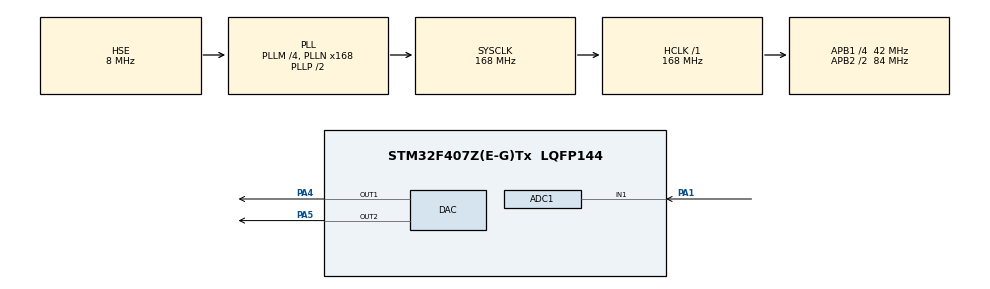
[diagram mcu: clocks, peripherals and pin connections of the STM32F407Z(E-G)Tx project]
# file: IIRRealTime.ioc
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ADC1.Channel-0\#ChannelRegularConversion=ADC_CHANNEL_1
ADC1.DMAContinuousRequests=ENABLE
ADC1.ExternalTrigConv=ADC_EXTERNALTRIGCONV_T8_TRGO
ADC1.NbrOfConversionFlag=1
ADC1.Rank-0\#ChannelRegularConversion=1
ADC1.SamplingTime-0\#ChannelRegularConversion=ADC_SAMPLETIME_3CYCLES
ADC1.master=1
DAC.DAC_Trigger=DAC_TRIGGER_T8_TRGO
DAC.DAC_Trigger2=DAC_TRIGGER_T8_TRGO
Dma.ADC1.0.Direction=DMA_PERIPH_TO_MEMORY
Dma.ADC1.0.FIFOMode=DMA_FIFOMODE_DISABLE
Dma.ADC1.0.Instance=DMA2_Stream0
Dma.ADC1.0.MemDataAlignment=DMA_MDATAALIGN_WORD
Dma.ADC1.0.MemInc=DMA_MINC_ENABLE
Dma.ADC1.0.Mode=DMA_CIRCULAR
Dma.ADC1.0.PeriphDataAlignment=DMA_PDATAALIGN_WORD
Dma.ADC1.0.PeriphInc=DMA_PINC_DISABLE
Dma.ADC1.0.Priority=DMA_PRIORITY_HIGH
Dma.DAC1.1.Direction=DMA_MEMORY_TO_PERIPH
Dma.DAC1.1.FIFOMode=DMA_FIFOMODE_DISABLE
Dma.DAC1.1.Instance=DMA1_Stream5
Dma.DAC1.1.MemDataAlignment=DMA_MDATAALIGN_WORD
Dma.DAC1.1.MemInc=DMA_MINC_ENABLE
Dma.DAC1.1.Mode=DMA_CIRCULAR
Dma.DAC1.1.PeriphDataAlignment=DMA_PDATAALIGN_WORD
Dma.DAC1.1.PeriphInc=DMA_PINC_DISABLE
Dma.DAC1.1.Priority=DMA_PRIORITY_HIGH
Dma.DAC2.2.Direction=DMA_MEMORY_TO_PERIPH
Dma.DAC2.2.FIFOMode=DMA_FIFOMODE_DISABLE
Dma.DAC2.2.Instance=DMA1_Stream6
Dma.DAC2.2.MemDataAlignment=DMA_MDATAALIGN_WORD
Dma.DAC2.2.MemInc=DMA_MINC_ENABLE
Dma.DAC2.2.Mode=DMA_CIRCULAR
Dma.DAC2.2.PeriphDataAlignment=DMA_PDATAALIGN_WORD
Dma.DAC2.2.PeriphInc=DMA_PINC_DISABLE
Dma.DAC2.2.Priority=DMA_PRIORITY_HIGH
Dma.Request0=ADC1
Dma.Request1=DAC1
Dma.Request2=DAC2
Mcu.Family=STM32F4
Mcu.Name=STM32F407Z(E-G)Tx
Mcu.Package=LQFP144
NVIC.DMA1_Stream5_IRQn=true\:0\:0\:false\:false\:true\:false\:true\:true
NVIC.DMA1_Stream6_IRQn=true\:0\:0\:false\:false\:true\:false\:true\:true
NVIC.DMA2_Stream0_IRQn=true\:0\:0\:false\:false\:true\:false\:true\:true
NVIC.PriorityGroup=NVIC_PRIORITYGROUP_4
PA1.Signal=ADCx_IN1
PA13.Mode=Serial_Wire
PA13.Signal=SYS_JTMS-SWDIO
PA14.Mode=Serial_Wire
PA14.Signal=SYS_JTCK-SWCLK
PA4.Signal=COMP_DAC1_group
PA5.Signal=COMP_DAC2_group
PH0-OSC_IN.Mode=HSE-External-Oscillator
PH0-OSC_IN.Signal=RCC_OSC_IN
PH1-OSC_OUT.Mode=HSE-External-Oscillator
PH1-OSC_OUT.Signal=RCC_OSC_OUT
ProjectManager.HeapSize=0x200
ProjectManager.StackSize=0x400
ProjectManager.TargetToolchain=STM32CubeIDE
RCC.48MHZClocksFreq_Value=84000000
RCC.AHBFreq_Value=168000000
RCC.APB1CLKDivider=RCC_HCLK_DIV4
RCC.APB1Freq_Value=42000000
RCC.APB1TimFreq_Value=84000000
RCC.APB2CLKDivider=RCC_HCLK_DIV2
RCC.APB2Freq_Value=84000000
RCC.APB2TimFreq_Value=168000000
RCC.CortexFreq_Value=168000000
RCC.HCLKFreq_Value=168000000
RCC.HSE_VALUE=8000000
RCC.HSI_VALUE=16000000
RCC.LSE_VALUE=32768
RCC.PLLM=4
RCC.PLLN=168
RCC.PLLSourceVirtual=RCC_PLLSOURCE_HSE
RCC.SYSCLKFreq_VALUE=168000000
RCC.SYSCLKSource=RCC_SYSCLKSOURCE_PLLCLK
RCC.VCOOutputFreq_Value=336000000
SH.ADCx_IN1.0=ADC1_IN1,IN1
SH.COMP_DAC1_group.0=DAC_OUT1,DAC_OUT1
SH.COMP_DAC2_group.0=DAC_OUT2,DAC_OUT2
TIM5.AutoReloadPreload=TIM_AUTORELOAD_PRELOAD_ENABLE
TIM5.Prescaler=83
TIM8.Period=3499
TIM8.TIM_MasterOutputTrigger=TIM_TRGO_UPDATE
VP_TIM5_VS_ClockSourceINT.Mode=Internal
VP_TIM8_VS_ClockSourceINT.Mode=Internal
board=custom

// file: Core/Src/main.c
/* USER CODE BEGIN Header */
/**
  ******************************************************************************
  * @file           : main.c
  * @brief          : Main program body
  ******************************************************************************
  * @attention
  *
  * Copyright (c) 2024 STMicroelectronics.
  * All rights reserved.
  *
  * This software is licensed under terms that can be found in the LICENSE file
  * in the root directory of this software component.
  * If no LICENSE file comes with this software, it is provided AS-IS.
  *
  ******************************************************************************
  */
/* USER CODE END Header */
#include "main.h"

/* USER CODE BEGIN Includes */
#include <string.h>

#define ARM_MATH_CM4

#include "arm_math.h"
/* USER CODE END Includes */

ADC_HandleTypeDef hadc1;
DMA_HandleTypeDef hdma_adc1;

DAC_HandleTypeDef hdac;
DMA_HandleTypeDef hdma_dac1;
DMA_HandleTypeDef hdma_dac2;

TIM_HandleTypeDef htim5;
TIM_HandleTypeDef htim8;

/* USER CODE BEGIN PV */

float32_t aIIR_F32_Coeffs[20] = {
	1,2.03045971006842,1.030928964547704,0.8350734723870988,-0.1809722302276889,
	1,1.99965252497197,1.000116453042647,0.8905975796378678,-0.2594951757406769,
	1,1.969540231281527,0.9699989009856418,1.015339858454558,-0.4359073982444064,
	1,2.000347533678088,0.9998835979072017,1.242773362694666,-0.7575469444788124
};

float32_t iirStateF32[16];

arm_biquad_casd_df1_inst_f32 IIR_F32_Struct;

//ADC DAC buffer
uint32_t adc_data[256];
uint32_t dac_data[256];
uint32_t sin_data[256];

float inBuffer[128];
float outBuffer[128];

uint32_t outDacFilter;
uint32_t outDacSignalGen;

uint8_t freq = 1;

/* USER CODE END PV */

void SystemClock_Config(void);
static void MX_GPIO_Init(void);
static void MX_DMA_Init(void);
static void MX_TIM5_Init(void);
static void MX_ADC1_Init(void);
static void MX_TIM8_Init(void);
static void MX_DAC_Init(void);
/* USER CODE BEGIN PFP */
void II_RProcess(void);
/* USER CODE END PFP */

int main(void)
{

  /* MCU Configuration--------------------------------------------------------*/

  /* Reset of all peripherals, Initializes the Flash interface and the Systick. */
  HAL_Init();

  /* Configure the system clock */
  SystemClock_Config();

  /* Initialize all configured peripherals */
  MX_GPIO_Init();
  MX_DMA_Init();
  MX_TIM5_Init();
  MX_ADC1_Init();
  MX_TIM8_Init();
  MX_DAC_Init();
  /* USER CODE BEGIN 2 */

  //generate output sin wave form
  for (int i = 0; i < 255; i++) {
	  sin_data[i] = (uint32_t)(1000*(sin(freq*2*3.1416*(((float)i)/256))+1));
  }

  arm_biquad_cascade_df1_init_f32(&IIR_F32_Struct, 4, aIIR_F32_Coeffs, iirStateF32);
  HAL_TIM_Base_Start(&htim8);
  HAL_ADC_Start_DMA(&hadc1, (uint32_t *) adc_data, 256);
  HAL_DAC_Start_DMA(&hdac, DAC_CHANNEL_1, (uint32_t *) dac_data, 256, DAC_ALIGN_12B_R);
  HAL_DAC_Start_DMA(&hdac, DAC_CHANNEL_2, (uint32_t *) sin_data, 256, DAC_ALIGN_12B_R);
  /* USER CODE END 2 */

  /* Infinite loop */
  while (1)
  {

  }
}

void SystemClock_Config(void)
{
  RCC_OscInitTypeDef RCC_OscInitStruct = {0};
  RCC_ClkInitTypeDef RCC_ClkInitStruct = {0};

  /** Configure the main internal regulator output voltage
  */
  __HAL_RCC_PWR_CLK_ENABLE();
  __HAL_PWR_VOLTAGESCALING_CONFIG(PWR_REGULATOR_VOLTAGE_SCALE1);

  /** Initializes the RCC Oscillators according to the specified parameters
  * in the RCC_OscInitTypeDef structure.
  */
  RCC_OscInitStruct.OscillatorType = RCC_OSCILLATORTYPE_HSE;
  RCC_OscInitStruct.HSEState = RCC_HSE_ON;
  RCC_OscInitStruct.PLL.PLLState = RCC_PLL_ON;
  RCC_OscInitStruct.PLL.PLLSource = RCC_PLLSOURCE_HSE;
  RCC_OscInitStruct.PLL.PLLM = 4;
  RCC_OscInitStruct.PLL.PLLN = 168;
  RCC_OscInitStruct.PLL.PLLP = RCC_PLLP_DIV2;
  RCC_OscInitStruct.PLL.PLLQ = 4;
  if (HAL_RCC_OscConfig(&RCC_OscInitStruct) != HAL_OK)
  {
    Error_Handler();
  }

  /** Initializes the CPU, AHB and APB buses clocks
  */
  RCC_ClkInitStruct.ClockType = RCC_CLOCKTYPE_HCLK|RCC_CLOCKTYPE_SYSCLK
                              |RCC_CLOCKTYPE_PCLK1|RCC_CLOCKTYPE_PCLK2;
  RCC_ClkInitStruct.SYSCLKSource = RCC_SYSCLKSOURCE_PLLCLK;
  RCC_ClkInitStruct.AHBCLKDivider = RCC_SYSCLK_DIV1;
  RCC_ClkInitStruct.APB1CLKDivider = RCC_HCLK_DIV4;
  RCC_ClkInitStruct.APB2CLKDivider = RCC_HCLK_DIV2;

  if (HAL_RCC_ClockConfig(&RCC_ClkInitStruct, FLASH_LATENCY_5) != HAL_OK)
  {
    Error_Handler();
  }
}

static void MX_ADC1_Init(void)
{

  ADC_ChannelConfTypeDef sConfig = {0};

  /** Configure the global features of the ADC (Clock, Resolution, Data Alignment and number of conversion)
  */
  hadc1.Instance = ADC1;
  hadc1.Init.ClockPrescaler = ADC_CLOCK_SYNC_PCLK_DIV4;
  hadc1.Init.Resolution = ADC_RESOLUTION_12B;
  hadc1.Init.ScanConvMode = DISABLE;
  hadc1.Init.ContinuousConvMode = DISABLE;
  hadc1.Init.DiscontinuousConvMode = DISABLE;
  hadc1.Init.ExternalTrigConvEdge = ADC_EXTERNALTRIGCONVEDGE_RISING;
  hadc1.Init.ExternalTrigConv = ADC_EXTERNALTRIGCONV_T8_TRGO;
  hadc1.Init.DataAlign = ADC_DATAALIGN_RIGHT;
  hadc1.Init.NbrOfConversion = 1;
  hadc1.Init.DMAContinuousRequests = ENABLE;
  hadc1.Init.EOCSelection = ADC_EOC_SINGLE_CONV;
  if (HAL_ADC_Init(&hadc1) != HAL_OK)
  {
    Error_Handler();
  }

  /** Configure for the selected ADC regular channel its corresponding rank in the sequencer and its sample time.
  */
  sConfig.Channel = ADC_CHANNEL_1;
  sConfig.Rank = 1;
  sConfig.SamplingTime = ADC_SAMPLETIME_3CYCLES;
  if (HAL_ADC_ConfigChannel(&hadc1, &sConfig) != HAL_OK)
  {
    Error_Handler();
  }

}

static void MX_DAC_Init(void)
{

  DAC_ChannelConfTypeDef sConfig = {0};

  /** DAC Initialization
  */
  hdac.Instance = DAC;
  if (HAL_DAC_Init(&hdac) != HAL_OK)
  {
    Error_Handler();
  }

  /** DAC channel OUT1 config
  */
  sConfig.DAC_Trigger = DAC_TRIGGER_T8_TRGO;
  sConfig.DAC_OutputBuffer = DAC_OUTPUTBUFFER_ENABLE;
  if (HAL_DAC_ConfigChannel(&hdac, &sConfig, DAC_CHANNEL_1) != HAL_OK)
  {
    Error_Handler();
  }

  /** DAC channel OUT2 config
  */
  if (HAL_DAC_ConfigChannel(&hdac, &sConfig, DAC_CHANNEL_2) != HAL_OK)
  {
    Error_Handler();
  }

}

static void MX_TIM5_Init(void)
{

  TIM_ClockConfigTypeDef sClockSourceConfig = {0};
  TIM_MasterConfigTypeDef sMasterConfig = {0};

  htim5.Instance = TIM5;
  htim5.Init.Prescaler = 83;
  htim5.Init.CounterMode = TIM_COUNTERMODE_UP;
  htim5.Init.Period = 4294967295;
  htim5.Init.ClockDivision = TIM_CLOCKDIVISION_DIV1;
  htim5.Init.AutoReloadPreload = TIM_AUTORELOAD_PRELOAD_ENABLE;
  if (HAL_TIM_Base_Init(&htim5) != HAL_OK)
  {
    Error_Handler();
  }
  sClockSourceConfig.ClockSource = TIM_CLOCKSOURCE_INTERNAL;
  if (HAL_TIM_ConfigClockSource(&htim5, &sClockSourceConfig) != HAL_OK)
  {
    Error_Handler();
  }
  sMasterConfig.MasterOutputTrigger = TIM_TRGO_RESET;
  sMasterConfig.MasterSlaveMode = TIM_MASTERSLAVEMODE_DISABLE;
  if (HAL_TIMEx_MasterConfigSynchronization(&htim5, &sMasterConfig) != HAL_OK)
  {
    Error_Handler();
  }
  /* USER CODE BEGIN TIM5_Init 2 */
  HAL_TIM_Base_Start(&htim5);
  /* USER CODE END TIM5_Init 2 */

}

static void MX_TIM8_Init(void)
{

  TIM_ClockConfigTypeDef sClockSourceConfig = {0};
  TIM_MasterConfigTypeDef sMasterConfig = {0};

  htim8.Instance = TIM8;
  htim8.Init.Prescaler = 0;
  htim8.Init.CounterMode = TIM_COUNTERMODE_UP;
  htim8.Init.Period = 3499;
  htim8.Init.ClockDivision = TIM_CLOCKDIVISION_DIV1;
  htim8.Init.RepetitionCounter = 0;
  htim8.Init.AutoReloadPreload = TIM_AUTORELOAD_PRELOAD_DISABLE;
  if (HAL_TIM_Base_Init(&htim8) != HAL_OK)
  {
    Error_Handler();
  }
  sClockSourceConfig.ClockSource = TIM_CLOCKSOURCE_INTERNAL;
  if (HAL_TIM_ConfigClockSource(&htim8, &sClockSourceConfig) != HAL_OK)
  {
    Error_Handler();
  }
  sMasterConfig.MasterOutputTrigger = TIM_TRGO_UPDATE;
  sMasterConfig.MasterSlaveMode = TIM_MASTERSLAVEMODE_DISABLE;
  if (HAL_TIMEx_MasterConfigSynchronization(&htim8, &sMasterConfig) != HAL_OK)
  {
    Error_Handler();
  }

}

static void MX_DMA_Init(void)
{

  /* DMA controller clock enable */
  __HAL_RCC_DMA2_CLK_ENABLE();
  __HAL_RCC_DMA1_CLK_ENABLE();

  /* DMA interrupt init */
  /* DMA1_Stream5_IRQn interrupt configuration */
  HAL_NVIC_SetPriority(DMA1_Stream5_IRQn, 0, 0);
  HAL_NVIC_EnableIRQ(DMA1_Stream5_IRQn);
  /* DMA1_Stream6_IRQn interrupt configuration */
  HAL_NVIC_SetPriority(DMA1_Stream6_IRQn, 0, 0);
  HAL_NVIC_EnableIRQ(DMA1_Stream6_IRQn);
  /* DMA2_Stream0_IRQn interrupt configuration */
  HAL_NVIC_SetPriority(DMA2_Stream0_IRQn, 0, 0);
  HAL_NVIC_EnableIRQ(DMA2_Stream0_IRQn);

}

static void MX_GPIO_Init(void)
{

  /* GPIO Ports Clock Enable */
  __HAL_RCC_GPIOH_CLK_ENABLE();
  __HAL_RCC_GPIOA_CLK_ENABLE();

}

/* USER CODE BEGIN 4 */
void HAL_ADC_ConvHalfCpltCallback(ADC_HandleTypeDef* hadc)
{
	for (int i = 0; i < 128; i++) {
		inBuffer[i] = (float)adc_data[i];
	}

	arm_biquad_cascade_df1_f32(&IIR_F32_Struct, (float32_t *)&inBuffer[0], (float32_t *)&outBuffer[0], 128);

	for (int i = 0; i < 128; i++) {
		dac_data[i] = (uint32_t)(0.00010791 * outBuffer[i]);
	}

	for (int i = 0; i < 128; i++) {
		sin_data[i] = (uint32_t)(1000*(sin(freq*2*3.1416*(((float)(i+128))/256))+1));
	}
}

void HAL_ADC_ConvCpltCallback(ADC_HandleTypeDef* hadc)
{
	for (int i = 0; i < 128; i++) {
		inBuffer[i] = (float)adc_data[i+128];
	}

	arm_biquad_cascade_df1_f32(&IIR_F32_Struct, (float32_t *)&inBuffer[0], (float32_t *)&outBuffer[0], 128);

	for (int i = 0; i < 128; i++) {
		dac_data[i+128] = (uint32_t)(0.00010791 * outBuffer[i]);
	}

	for (int i = 0; i < 128; i++) {
		sin_data[i+128] = (uint32_t)(1000*(sin(freq*2*3.1416*(((float)i)/256))+1));
	}
}

/* USER CODE END 4 */

void Error_Handler(void)
{
  __disable_irq();
  while (1)
  {
  }
}
